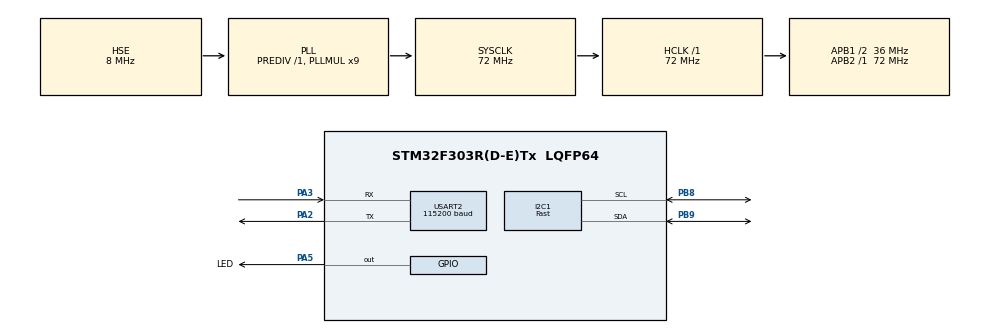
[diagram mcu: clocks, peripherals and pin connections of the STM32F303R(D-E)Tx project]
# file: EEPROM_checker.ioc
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Mcu.Family=STM32F3
RCC.PLLSourceVirtual=RCC_PLLSOURCE_HSE
RCC.CortexFreq_Value=72000000
Dma.USART2_TX.0.MemInc=DMA_MINC_ENABLE
Dma.USART2_TX.0.PeriphDataAlignment=DMA_PDATAALIGN_BYTE
I2C1.I2C_Speed_Mode=I2C_Fast
RCC.SYSCLKSourceVirtual=RCC_SYSCLKSOURCE_PLLCLK
RCC.APB1CLKDivider=RCC_HCLK_DIV2
NVIC.USART2_IRQn=true\:0\:0\:false\:false\:true\:true\:true
USART2.BaudRate=115200
ProjectManager.StackSize=0x400
PA13.Signal=SYS_JTMS-SWDIO
PA3.Mode=Asynchronous
Dma.USART2_TX.0.Priority=DMA_PRIORITY_LOW
ProjectManager.TargetToolchain=STM32CubeIDE
RCC.HCLKFreq_Value=72000000
PB9.Mode=I2C
RCC.APB2TimFreq_Value=72000000
I2C1.Timing=0x0000020B
RCC.USBFreq_Value=72000000
RCC.LSE_VALUE=32768
RCC.AHBFreq_Value=72000000
PF0-OSC_IN.Mode=HSE-External-Oscillator
PA5.Signal=GPIO_Output
RCC.HSE_VALUE=8000000
board=custom
USART2.VirtualMode-Asynchronous=VM_ASYNC
RCC.PLLMUL=RCC_PLL_MUL9
RCC.APB2Freq_Value=72000000
PA14.Mode=Serial_Wire
Dma.USART2_TX.0.MemDataAlignment=DMA_MDATAALIGN_BYTE
PA13.Mode=Serial_Wire
Dma.USART2_TX.0.Direction=DMA_MEMORY_TO_PERIPH
Mcu.Name=STM32F303R(D-E)Tx
Dma.USART2_TX.0.Instance=DMA1_Channel7
PA2.Signal=USART2_TX
RCC.SYSCLKFreq_VALUE=72000000
Mcu.Package=LQFP64
PB9.Signal=I2C1_SDA
Dma.USART2_TX.0.PeriphInc=DMA_PINC_DISABLE
PA5.GPIO_Label=LED
PA14.Signal=SYS_JTCK-SWCLK
ProjectManager.HeapSize=0x200
PB9.GPIO_PuPdOD=GPIO_NOPULL
PB8.GPIO_PuPdOD=GPIO_NOPULL
RCC.HSI_VALUE=8000000
Dma.USART2_TX.0.Mode=DMA_NORMAL
NVIC.PriorityGroup=NVIC_PRIORITYGROUP_4
PB8.Mode=I2C
RCC.APB1TimFreq_Value=72000000
PA2.Mode=Asynchronous
PB8.Signal=I2C1_SCL
NVIC.DMA1_Channel7_IRQn=true\:0\:0\:false\:false\:true\:false\:true
PF0-OSC_IN.Signal=RCC_OSC_IN
PF1-OSC_OUT.Mode=HSE-External-Oscillator
RCC.APB1Freq_Value=36000000
Dma.Request0=USART2_TX
PF1-OSC_OUT.Signal=RCC_OSC_OUT
PA3.Signal=USART2_RX

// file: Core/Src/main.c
/* USER CODE BEGIN Header */
/**
  ******************************************************************************
  * @file           : main.c
  * @brief          : Main program body
  ******************************************************************************
  * @attention
  *
  * <h2><center>&copy; Copyright (c) 2021 STMicroelectronics.
  * All rights reserved.</center></h2>
  *
  * This software component is licensed by ST under BSD 3-Clause license,
  * the "License"; You may not use this file except in compliance with the
  * License. You may obtain a copy of the License at:
  *                        opensource.org/licenses/BSD-3-Clause
  *
  ******************************************************************************
  */
/* USER CODE END Header */
#include "main.h"
#include "dma.h"
#include "i2c.h"
#include "usart.h"
#include "gpio.h"

/* USER CODE BEGIN Includes */

#include "StateMachine.h"

/* USER CODE END Includes */

void SystemClock_Config(void);

int main(void)
{

  /* MCU Configuration--------------------------------------------------------*/

  /* Reset of all peripherals, Initializes the Flash interface and the Systick. */
  HAL_Init();

  /* Configure the system clock */
  SystemClock_Config();

  /* Initialize all configured peripherals */
  MX_GPIO_Init();
  MX_DMA_Init();
  MX_I2C1_Init();
  MX_USART2_UART_Init();

  /* Infinite loop */
  /* USER CODE BEGIN WHILE */
  while (1)
  {
	  StateMachineHandle();

    /* USER CODE END WHILE */

  }
}

void SystemClock_Config(void)
{
  RCC_OscInitTypeDef RCC_OscInitStruct = {0};
  RCC_ClkInitTypeDef RCC_ClkInitStruct = {0};
  RCC_PeriphCLKInitTypeDef PeriphClkInit = {0};

  /** Initializes the RCC Oscillators according to the specified parameters
  * in the RCC_OscInitTypeDef structure.
  */
  RCC_OscInitStruct.OscillatorType = RCC_OSCILLATORTYPE_HSI|RCC_OSCILLATORTYPE_HSE;
  RCC_OscInitStruct.HSEState = RCC_HSE_ON;
  RCC_OscInitStruct.HSIState = RCC_HSI_ON;
  RCC_OscInitStruct.HSICalibrationValue = RCC_HSICALIBRATION_DEFAULT;
  RCC_OscInitStruct.PLL.PLLState = RCC_PLL_ON;
  RCC_OscInitStruct.PLL.PLLSource = RCC_PLLSOURCE_HSE;
  RCC_OscInitStruct.PLL.PLLMUL = RCC_PLL_MUL9;
  RCC_OscInitStruct.PLL.PREDIV = RCC_PREDIV_DIV1;
  if (HAL_RCC_OscConfig(&RCC_OscInitStruct) != HAL_OK)
  {
    Error_Handler();
  }
  /** Initializes the CPU, AHB and APB buses clocks
  */
  RCC_ClkInitStruct.ClockType = RCC_CLOCKTYPE_HCLK|RCC_CLOCKTYPE_SYSCLK
                              |RCC_CLOCKTYPE_PCLK1|RCC_CLOCKTYPE_PCLK2;
  RCC_ClkInitStruct.SYSCLKSource = RCC_SYSCLKSOURCE_PLLCLK;
  RCC_ClkInitStruct.AHBCLKDivider = RCC_SYSCLK_DIV1;
  RCC_ClkInitStruct.APB1CLKDivider = RCC_HCLK_DIV2;
  RCC_ClkInitStruct.APB2CLKDivider = RCC_HCLK_DIV1;

  if (HAL_RCC_ClockConfig(&RCC_ClkInitStruct, FLASH_LATENCY_2) != HAL_OK)
  {
    Error_Handler();
  }
  PeriphClkInit.PeriphClockSelection = RCC_PERIPHCLK_USART2|RCC_PERIPHCLK_I2C1;
  PeriphClkInit.Usart2ClockSelection = RCC_USART2CLKSOURCE_PCLK1;
  PeriphClkInit.I2c1ClockSelection = RCC_I2C1CLKSOURCE_HSI;
  if (HAL_RCCEx_PeriphCLKConfig(&PeriphClkInit) != HAL_OK)
  {
    Error_Handler();
  }
}

void Error_Handler(void)
{
  __disable_irq();
  while (1)
  {
  }
}

/************************ (C) COPYRIGHT STMicroelectronics *****END OF FILE****/
